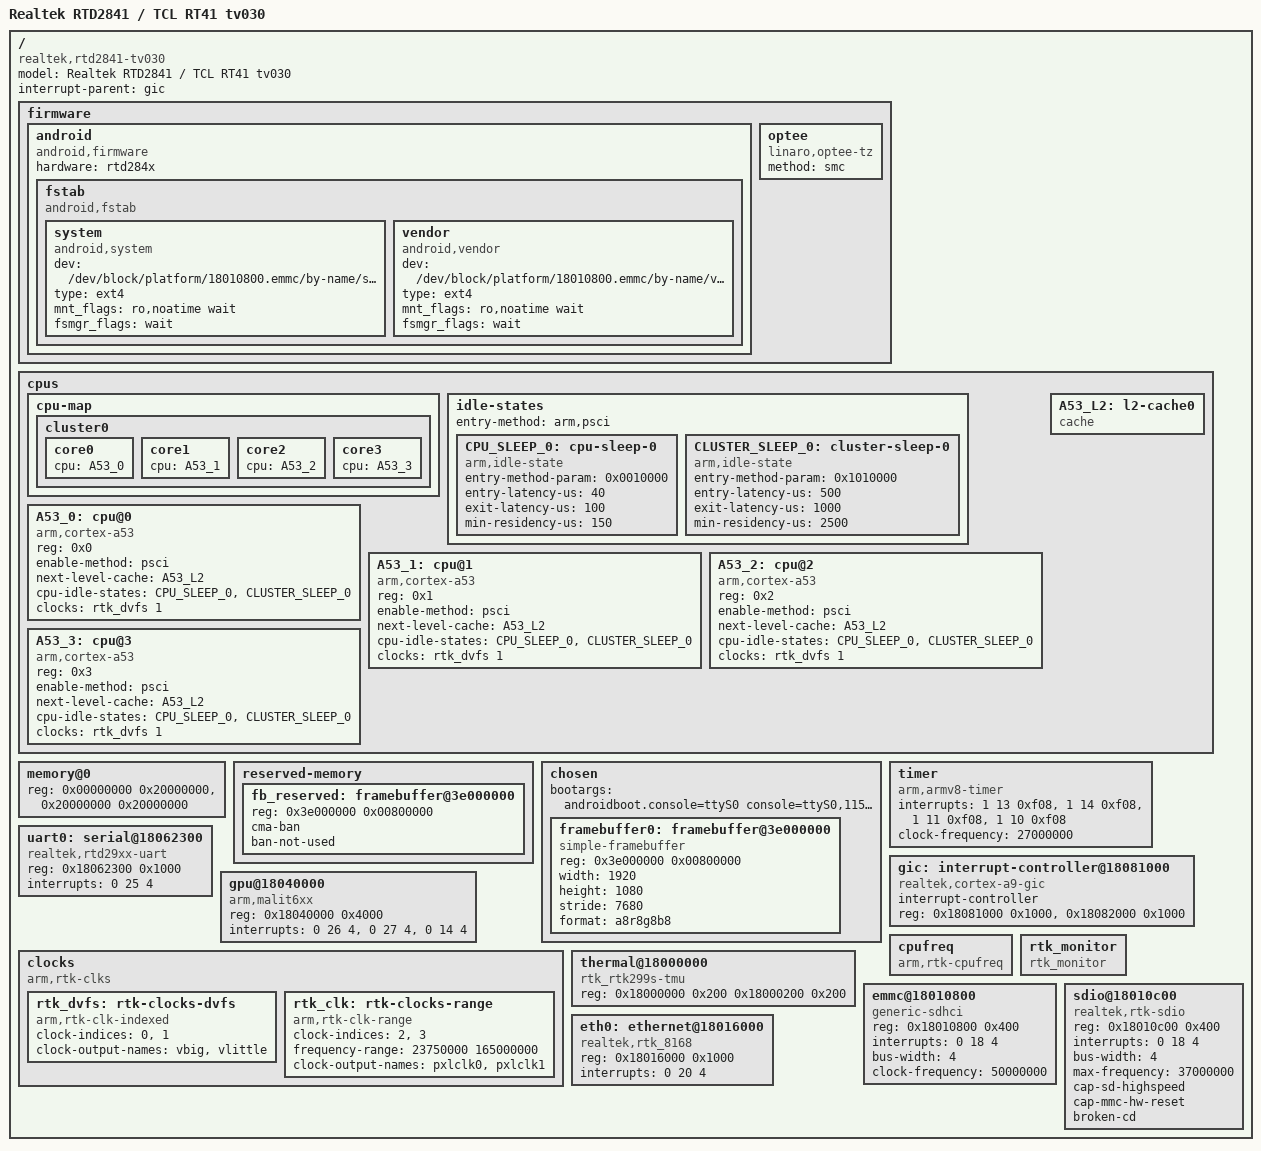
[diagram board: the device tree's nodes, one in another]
/*
 * Realtek RTD284x / RTD299s Device Tree Source
 * Target: TCL Smart TV RT41 Chassis (Board Profile tv030)
 *
 * Silicon Lineage & Compatibility Architecture:
 * - Realtek's vendor BSP (Linux 4.4.3 RTK tree) designates "rtk,rtd299s" as the
 *   baseline silicon IP generation compatible identifier for the RTD284x SoC family.
 * - Production firmware for board profile 'tv030' (TCL RT41DT chassis) inherits
 *   the rtd299s IP block topology and peripheral register layout.
 * - Hardware target: Cortex-A53 quad-core, GIC-400, 16550A UART, Realtek RBUS.
 */

/dts-v1/;
/include/ "skeleton.dtsi"

/ {
	model = "Realtek RTD2841 / TCL RT41 tv030";
	compatible = "realtek,rtd2841-tv030", "realtek,rtd284x", "rtk,rtd299s";
	interrupt-parent = <&gic>;

        firmware {
            android {
               compatible = "android,firmware";
               hardware = "rtd284x";
            fstab {
               compatible = "android,fstab";
            system {
               compatible = "android,system";
               dev = "/dev/block/platform/18010800.emmc/by-name/system";
               type = "ext4";
               mnt_flags = "ro,noatime wait";
               fsmgr_flags = "wait";
            };
            vendor {
               compatible = "android,vendor";
               dev = "/dev/block/platform/18010800.emmc/by-name/vendor";
               type = "ext4";
               mnt_flags = "ro,noatime wait";
               fsmgr_flags = "wait";
            };
            };
            };
        };

	cpus {
		#address-cells = <1>;
		#size-cells = <0>;

		cpu-map {
			cluster0: cluster0 {
				#cooling-cells = <2>; /* min followed by max */

				core0 {
					cpu = <&A53_0>;
				};

				core1 {
					cpu = <&A53_1>;
				};
				core2 {
					cpu = <&A53_2>;
				};
				core3 {
					cpu = <&A53_3>;
				};

			};

		};

		idle-states {
			entry-method = "arm,psci";

			CPU_SLEEP_0: cpu-sleep-0 {
				compatible = "arm,idle-state";
				entry-method-param = <0x0010000>;
				entry-latency-us = <40>;
				exit-latency-us = <100>;
				min-residency-us = <150>;
			};

			CLUSTER_SLEEP_0: cluster-sleep-0 {
				compatible = "arm,idle-state";
				entry-method-param = <0x1010000>;
				entry-latency-us = <500>;
				exit-latency-us = <1000>;
				min-residency-us = <2500>;
			};
		};

		A53_0: cpu@0 {
			compatible = "arm,cortex-a53","arm,armv8";
			reg = <0x0>;
			device_type = "cpu";
			enable-method = "psci";
                        next-level-cache = <&A53_L2>;
			cpu-idle-states = <&CPU_SLEEP_0 &CLUSTER_SLEEP_0>;
			clocks = <&rtk_dvfs 1>;
			clock-names = "vlittle";
		};

		A53_1: cpu@1 {
			compatible = "arm,cortex-a53","arm,armv8";
			reg = <0x1>;
			device_type = "cpu";
			enable-method = "psci";
                        next-level-cache = <&A53_L2>;
			cpu-idle-states = <&CPU_SLEEP_0 &CLUSTER_SLEEP_0>;
			clocks = <&rtk_dvfs 1>;
			clock-names = "vlittle";
		};
		A53_2: cpu@2 {
			compatible = "arm,cortex-a53","arm,armv8";
			reg = <0x2>;
			device_type = "cpu";
			enable-method = "psci";
                        next-level-cache = <&A53_L2>;
			cpu-idle-states = <&CPU_SLEEP_0 &CLUSTER_SLEEP_0>;
			clocks = <&rtk_dvfs 1>;
			clock-names = "vlittle";
		};

		A53_3: cpu@3 {
			compatible = "arm,cortex-a53","arm,armv8";
			reg = <0x3>;
			device_type = "cpu";
			enable-method = "psci";
                        next-level-cache = <&A53_L2>;
			cpu-idle-states = <&CPU_SLEEP_0 &CLUSTER_SLEEP_0>;
			clocks = <&rtk_dvfs 1>;
			clock-names = "vlittle";
		};


                A53_L2: l2-cache0 {
                        compatible = "cache";
                };

	};

	memory@0 {
		device_type = "memory";
		reg = <0x00000000 0x20000000>,
		      <0x20000000 0x20000000>;
	};

        reserved-memory {
                #address-cells = <1>;
                #size-cells = <1>;
                ranges;

                fb_reserved: framebuffer@3e000000 {
                        reg = <0x3e000000 0x00800000>;
                        cma-ban;
                        ban-not-used;
                };
        };

        firmware {
                optee {
                        compatible = "linaro,optee-tz";
                        method = "smc";
                };
        };

	chosen {
		#address-cells = <1>;
		#size-cells = <1>;
		ranges;
		bootargs ="androidboot.console=ttyS0 console=ttyS0,115200 ignore_loglevel initcall_debug flashtype=emmc earlyprintk root=/dev/mmcblk0p1 rootfstype=ext4 rw rootwait";
		framebuffer0: framebuffer@3e000000 {
			compatible = "simple-framebuffer";
			reg = <0x3e000000 0x00800000>;
			width = <1920>;
			height = <1080>;
			stride = <7680>;
			format = "a8r8g8b8";
			status = "okay";
		};
	};


	timer {
		compatible = "arm,armv8-timer", "arm,armv7-timer";
		interrupts = <1 13 0xf08>,
			     <1 14 0xf08>,
			     <1 11 0xf08>,
			     <1 10 0xf08>;
		clock-frequency = <27000000>;
	};

	gic: interrupt-controller@18081000 {
		compatible = "realtek,cortex-a9-gic";
		#interrupt-cells = <3>;
		interrupt-controller;
		reg = <0x18081000 0x1000>,    /* gic dist base */
			<0x18082000 0x1000>;    /* gic cpu base  */
	};

	uart0: serial@18062300 {
		compatible = "realtek,rtd29xx-uart";
		reg = <0x18062300 0x1000>;
		interrupts = <0 25 4>;
	};

	gpu@18040000 {
		compatible = "arm,malit6xx", "arm,mali-midgard";
		reg = <0x18040000 0x4000>;
		interrupts = <0 26 4>, <0 27 4>, <0 14 4>;
		interrupt-names = "JOB", "MMU", "GPU";

		//clocks = <&pclk_mali>;
		clock-names = "clk_mali";
	};

       clocks {
               compatible = "arm,rtk-clks";

                rtk_dvfs: rtk-clocks-dvfs {
                        compatible = "arm,rtk-clk-indexed";
                        #clock-cells = <1>;
                        clock-indices = <0>, <1>;
                        clock-output-names = "vbig", "vlittle";
                };

                rtk_clk: rtk-clocks-range {
                        compatible = "arm,rtk-clk-range";
                        #clock-cells = <1>;
                        clock-indices = <2>, <3>;
                        frequency-range = <23750000 165000000>;
                        clock-output-names = "pxlclk0", "pxlclk1";
                };
       };

        cpufreq {
                compatible = "arm,rtk-cpufreq";
        };

	thermal@18000000 {
        	compatible = "rtk_rtk299s-tmu";
        	reg = <0x18000000 0x200
        	       0x18000200 0x200>;
        	status = "okay";
        };

        rtk_monitor {
                compatible = "rtk_monitor";
                status = "okay";
        };

	emmc@18010800 {
		compatible = "generic-sdhci", "realtek,rtd2841-sdhci", "realtek,rtk-emmc";
		reg = <0x18010800 0x400>;
		interrupts = <0 18 4>;
		bus-width = <4>;
		clock-frequency = <50000000>;
		status = "okay";
	};

	sdio@18010c00 {
		compatible = "realtek,rtk-sdio";
		reg = <0x18010c00 0x400>;
		interrupts = <0 18 4>;
		bus-width = <4>;
		max-frequency = <37000000>;
		cap-sd-highspeed;
		cap-mmc-hw-reset;
		broken-cd;
	};

	eth0: ethernet@18016000 {
		compatible = "realtek,rtk_8168";
		reg = <0x18016000 0x1000>;
		interrupts = <0 20 4>;
		status = "okay";
	};
};
